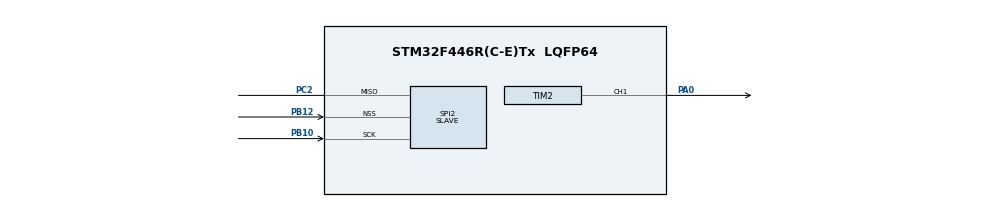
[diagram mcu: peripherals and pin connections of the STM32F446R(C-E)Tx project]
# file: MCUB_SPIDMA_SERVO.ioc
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Dma.Request0=SPI2_RX
Dma.SPI2_RX.0.Direction=DMA_PERIPH_TO_MEMORY
Dma.SPI2_RX.0.FIFOMode=DMA_FIFOMODE_DISABLE
Dma.SPI2_RX.0.Instance=DMA1_Stream3
Dma.SPI2_RX.0.MemDataAlignment=DMA_MDATAALIGN_BYTE
Dma.SPI2_RX.0.MemInc=DMA_MINC_ENABLE
Dma.SPI2_RX.0.Mode=DMA_NORMAL
Dma.SPI2_RX.0.PeriphDataAlignment=DMA_PDATAALIGN_BYTE
Dma.SPI2_RX.0.PeriphInc=DMA_PINC_DISABLE
Dma.SPI2_RX.0.Priority=DMA_PRIORITY_HIGH
Mcu.Family=STM32F4
Mcu.Name=STM32F446R(C-E)Tx
Mcu.Package=LQFP64
NVIC.DMA1_Stream3_IRQn=true\:0\:0\:false\:false\:true\:false\:true\:true
NVIC.PriorityGroup=NVIC_PRIORITYGROUP_4
PA0-WKUP.Signal=S_TIM2_CH1_ETR
PB10.Mode=Simplex_Bidirectional_Slave
PB10.Signal=SPI2_SCK
PB12.Mode=NSS_Signal_Hard_Input
PB12.Signal=SPI2_NSS
PC2.Mode=Simplex_Bidirectional_Slave
PC2.Signal=SPI2_MISO
ProjectManager.HeapSize=0x200
ProjectManager.StackSize=0x400
ProjectManager.TargetToolchain=MDK-ARM V5.32
RCC.AHBFreq_Value=16000000
RCC.APB1Freq_Value=16000000
RCC.APB1TimFreq_Value=16000000
RCC.APB2Freq_Value=16000000
RCC.APB2TimFreq_Value=16000000
RCC.CortexFreq_Value=16000000
RCC.HCLKFreq_Value=16000000
RCC.SYSCLKFreq_VALUE=16000000
RCC.USBFreq_Value=96000000
RCC.VCOOutputFreq_Value=192000000
SH.S_TIM2_CH1_ETR.0=TIM2_CH1,PWM Generation1 CH1
SPI2.Direction=SPI_DIRECTION_1LINE
SPI2.Mode=SPI_MODE_SLAVE
SPI2.VirtualNSS=VM_NSSHARD
SPI2.VirtualType=VM_SLAVE
TIM2.Channel-PWM\ Generation1\ CH1=TIM_CHANNEL_1
TIM2.Period=1999
TIM2.Prescaler=159
TIM2.Pulse-PWM\ Generation1\ CH1=150
board=custom

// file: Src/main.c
/* USER CODE BEGIN Header */
/**
  ******************************************************************************
  * @file           : main.c
  * @brief          : Main program body
  ******************************************************************************
  * @attention
  *
  * Copyright (c) 2024 STMicroelectronics.
  * All rights reserved.
  *
  * This software is licensed under terms that can be found in the LICENSE file
  * in the root directory of this software component.
  * If no LICENSE file comes with this software, it is provided AS-IS.
  *
  ******************************************************************************
  */
/* USER CODE END Header */
#include "main.h"

/* USER CODE BEGIN PV */
__IO uint8_t spi_rx_buffer;  // Buffer to hold received SPI data
__IO uint16_t servo_pulse_value; // Pulse width value for PWM
/* USER CODE END PV */

void SystemClock_Config(void);
static void MX_GPIO_Init(void);
static void MX_DMA_Init(void);
static void MX_SPI2_Init(void);
static void MX_TIM2_Init(void);

int main(void)
{

  /* MCU Configuration--------------------------------------------------------*/

  /* Reset of all peripherals, Initializes the Flash interface and the Systick. */
  LL_APB2_GRP1_EnableClock(LL_APB2_GRP1_PERIPH_SYSCFG);
  LL_APB1_GRP1_EnableClock(LL_APB1_GRP1_PERIPH_PWR);

  /* System interrupt init*/
  NVIC_SetPriorityGrouping(NVIC_PRIORITYGROUP_4);

  /* SysTick_IRQn interrupt configuration */
  NVIC_SetPriority(SysTick_IRQn, NVIC_EncodePriority(NVIC_GetPriorityGrouping(),15, 0));

  /* Configure the system clock */
  SystemClock_Config();

  /* Initialize all configured peripherals */
  MX_GPIO_Init();
  MX_DMA_Init();
  MX_SPI2_Init();
  MX_TIM2_Init();
  /* USER CODE BEGIN 2 */
	LL_TIM_EnableCounter(TIM2);

	LL_TIM_CC_EnableChannel(TIM2, LL_TIM_CHANNEL_CH1);
  LL_TIM_EnableAllOutputs(TIM2);

	LL_SPI_EnableDMAReq_RX(SPI2);
  LL_DMA_EnableStream(DMA1, LL_DMA_STREAM_3);

	LL_TIM_OC_SetCompareCH1(TIM2, 50);
  /* USER CODE END 2 */

  /* Infinite loop */
  while (1)
  {
		servo_pulse_value = 50 + ((spi_rx_buffer * (250 - 50)) / 180); // Map angle to PWM pulse width
    LL_TIM_OC_SetCompareCH1(TIM2, servo_pulse_value);
  }
}

void SystemClock_Config(void)
{
  LL_FLASH_SetLatency(LL_FLASH_LATENCY_0);
  while(LL_FLASH_GetLatency()!= LL_FLASH_LATENCY_0)
  {
  }
  LL_PWR_SetRegulVoltageScaling(LL_PWR_REGU_VOLTAGE_SCALE3);
  LL_PWR_DisableOverDriveMode();
  LL_RCC_HSI_SetCalibTrimming(16);
  LL_RCC_HSI_Enable();

   /* Wait till HSI is ready */
  while(LL_RCC_HSI_IsReady() != 1)
  {

  }
  LL_RCC_SetAHBPrescaler(LL_RCC_SYSCLK_DIV_1);
  LL_RCC_SetAPB1Prescaler(LL_RCC_APB1_DIV_1);
  LL_RCC_SetAPB2Prescaler(LL_RCC_APB2_DIV_1);
  LL_RCC_SetSysClkSource(LL_RCC_SYS_CLKSOURCE_HSI);

   /* Wait till System clock is ready */
  while(LL_RCC_GetSysClkSource() != LL_RCC_SYS_CLKSOURCE_STATUS_HSI)
  {

  }
  LL_Init1msTick(16000000);
  LL_SetSystemCoreClock(16000000);
  LL_RCC_SetTIMPrescaler(LL_RCC_TIM_PRESCALER_TWICE);
}

static void MX_SPI2_Init(void)
{

  LL_SPI_InitTypeDef SPI_InitStruct = {0};

  LL_GPIO_InitTypeDef GPIO_InitStruct = {0};

  /* Peripheral clock enable */
  LL_APB1_GRP1_EnableClock(LL_APB1_GRP1_PERIPH_SPI2);

  LL_AHB1_GRP1_EnableClock(LL_AHB1_GRP1_PERIPH_GPIOC);
  LL_AHB1_GRP1_EnableClock(LL_AHB1_GRP1_PERIPH_GPIOB);
  /**SPI2 GPIO Configuration
  PC2   ------> SPI2_MISO
  PB10   ------> SPI2_SCK
  PB12   ------> SPI2_NSS
  */
  GPIO_InitStruct.Pin = LL_GPIO_PIN_2;
  GPIO_InitStruct.Mode = LL_GPIO_MODE_ALTERNATE;
  GPIO_InitStruct.Speed = LL_GPIO_SPEED_FREQ_VERY_HIGH;
  GPIO_InitStruct.OutputType = LL_GPIO_OUTPUT_PUSHPULL;
  GPIO_InitStruct.Pull = LL_GPIO_PULL_NO;
  GPIO_InitStruct.Alternate = LL_GPIO_AF_5;
  LL_GPIO_Init(GPIOC, &GPIO_InitStruct);

  GPIO_InitStruct.Pin = LL_GPIO_PIN_10|LL_GPIO_PIN_12;
  GPIO_InitStruct.Mode = LL_GPIO_MODE_ALTERNATE;
  GPIO_InitStruct.Speed = LL_GPIO_SPEED_FREQ_VERY_HIGH;
  GPIO_InitStruct.OutputType = LL_GPIO_OUTPUT_PUSHPULL;
  GPIO_InitStruct.Pull = LL_GPIO_PULL_NO;
  GPIO_InitStruct.Alternate = LL_GPIO_AF_5;
  LL_GPIO_Init(GPIOB, &GPIO_InitStruct);

  /* SPI2 DMA Init */

  /* SPI2_RX Init */
  LL_DMA_SetChannelSelection(DMA1, LL_DMA_STREAM_3, LL_DMA_CHANNEL_0);

  LL_DMA_SetDataTransferDirection(DMA1, LL_DMA_STREAM_3, LL_DMA_DIRECTION_PERIPH_TO_MEMORY);

  LL_DMA_SetStreamPriorityLevel(DMA1, LL_DMA_STREAM_3, LL_DMA_PRIORITY_HIGH);

  LL_DMA_SetMode(DMA1, LL_DMA_STREAM_3, LL_DMA_MODE_CIRCULAR);

  LL_DMA_SetPeriphIncMode(DMA1, LL_DMA_STREAM_3, LL_DMA_PERIPH_NOINCREMENT);

  LL_DMA_SetMemoryIncMode(DMA1, LL_DMA_STREAM_3, LL_DMA_MEMORY_INCREMENT);

  LL_DMA_SetPeriphSize(DMA1, LL_DMA_STREAM_3, LL_DMA_PDATAALIGN_BYTE);

  LL_DMA_SetMemorySize(DMA1, LL_DMA_STREAM_3, LL_DMA_MDATAALIGN_BYTE);

  LL_DMA_DisableFifoMode(DMA1, LL_DMA_STREAM_3);

  /* USER CODE BEGIN SPI2_Init 1 */
	LL_DMA_SetPeriphAddress(DMA1, LL_DMA_STREAM_3, (uint32_t)&SPI2->DR);

  LL_DMA_SetMemoryAddress(DMA1, LL_DMA_STREAM_3, (uint32_t)&spi_rx_buffer);

	LL_DMA_SetDataLength(DMA1, LL_DMA_STREAM_3, 1);
  /* USER CODE END SPI2_Init 1 */
  /* SPI2 parameter configuration*/
  SPI_InitStruct.TransferDirection = LL_SPI_HALF_DUPLEX_RX;
  SPI_InitStruct.Mode = LL_SPI_MODE_SLAVE;
  SPI_InitStruct.DataWidth = LL_SPI_DATAWIDTH_8BIT;
  SPI_InitStruct.ClockPolarity = LL_SPI_POLARITY_LOW;
  SPI_InitStruct.ClockPhase = LL_SPI_PHASE_1EDGE;
  SPI_InitStruct.NSS = LL_SPI_NSS_HARD_INPUT;
  SPI_InitStruct.BitOrder = LL_SPI_MSB_FIRST;
  SPI_InitStruct.CRCCalculation = LL_SPI_CRCCALCULATION_DISABLE;
  SPI_InitStruct.CRCPoly = 10;
  LL_SPI_Init(SPI2, &SPI_InitStruct);
  LL_SPI_SetStandard(SPI2, LL_SPI_PROTOCOL_MOTOROLA);
  /* USER CODE BEGIN SPI2_Init 2 */
	LL_SPI_Enable(SPI2);
  /* USER CODE END SPI2_Init 2 */

}

static void MX_TIM2_Init(void)
{

  LL_TIM_InitTypeDef TIM_InitStruct = {0};
  LL_TIM_OC_InitTypeDef TIM_OC_InitStruct = {0};

  LL_GPIO_InitTypeDef GPIO_InitStruct = {0};

  /* Peripheral clock enable */
  LL_APB1_GRP1_EnableClock(LL_APB1_GRP1_PERIPH_TIM2);

  TIM_InitStruct.Prescaler = 159;
  TIM_InitStruct.CounterMode = LL_TIM_COUNTERMODE_UP;
  TIM_InitStruct.Autoreload = 1999;
  TIM_InitStruct.ClockDivision = LL_TIM_CLOCKDIVISION_DIV1;
  LL_TIM_Init(TIM2, &TIM_InitStruct);
  LL_TIM_DisableARRPreload(TIM2);
  LL_TIM_OC_EnablePreload(TIM2, LL_TIM_CHANNEL_CH1);
  TIM_OC_InitStruct.OCMode = LL_TIM_OCMODE_PWM1;
  TIM_OC_InitStruct.OCState = LL_TIM_OCSTATE_DISABLE;
  TIM_OC_InitStruct.OCNState = LL_TIM_OCSTATE_DISABLE;
  TIM_OC_InitStruct.CompareValue = 150;
  TIM_OC_InitStruct.OCPolarity = LL_TIM_OCPOLARITY_HIGH;
  LL_TIM_OC_Init(TIM2, LL_TIM_CHANNEL_CH1, &TIM_OC_InitStruct);
  LL_TIM_OC_DisableFast(TIM2, LL_TIM_CHANNEL_CH1);
  LL_TIM_SetTriggerOutput(TIM2, LL_TIM_TRGO_RESET);
  LL_TIM_DisableMasterSlaveMode(TIM2);
  LL_AHB1_GRP1_EnableClock(LL_AHB1_GRP1_PERIPH_GPIOA);
  /**TIM2 GPIO Configuration
  PA0-WKUP   ------> TIM2_CH1
  */
  GPIO_InitStruct.Pin = LL_GPIO_PIN_0;
  GPIO_InitStruct.Mode = LL_GPIO_MODE_ALTERNATE;
  GPIO_InitStruct.Speed = LL_GPIO_SPEED_FREQ_LOW;
  GPIO_InitStruct.OutputType = LL_GPIO_OUTPUT_PUSHPULL;
  GPIO_InitStruct.Pull = LL_GPIO_PULL_NO;
  GPIO_InitStruct.Alternate = LL_GPIO_AF_1;
  LL_GPIO_Init(GPIOA, &GPIO_InitStruct);

}

static void MX_DMA_Init(void)
{

  /* Init with LL driver */
  /* DMA controller clock enable */
  LL_AHB1_GRP1_EnableClock(LL_AHB1_GRP1_PERIPH_DMA1);

  /* DMA interrupt init */
  /* DMA1_Stream3_IRQn interrupt configuration */
  NVIC_SetPriority(DMA1_Stream3_IRQn, NVIC_EncodePriority(NVIC_GetPriorityGrouping(),0, 0));
  NVIC_EnableIRQ(DMA1_Stream3_IRQn);

}

static void MX_GPIO_Init(void)
{

  /* GPIO Ports Clock Enable */
  LL_AHB1_GRP1_EnableClock(LL_AHB1_GRP1_PERIPH_GPIOC);
  LL_AHB1_GRP1_EnableClock(LL_AHB1_GRP1_PERIPH_GPIOA);
  LL_AHB1_GRP1_EnableClock(LL_AHB1_GRP1_PERIPH_GPIOB);

}

void Error_Handler(void)
{
  __disable_irq();
  while (1)
  {
  }
}
